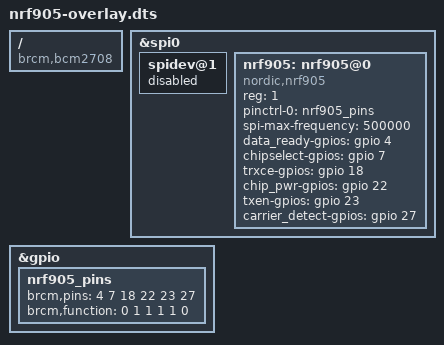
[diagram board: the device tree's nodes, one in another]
// Overlay for the Nordic Semiconductor NRF905 tranceiver
/dts-v1/;
/plugin/;

/ {
	compatible = "brcm,bcm2708";

	fragment@0 {
		target = <&spi0>;
		__overlay__ {
			#address-cells = <1>;
			#size-cells = <0>;

			status = "okay";

			spidev@1{
				status = "disabled";
			};

			nrf905: nrf905@0 {
				compatible = "nordic,nrf905";
				reg = <1>;
				pinctrl-names = "default";
				pinctrl-0 = <&nrf905_pins>;
				#address-cells = <1>;
				#size-cells = <0>;
				spi-max-frequency = <500000>;
				data_ready-gpios = <&gpio 4 0>;
				chipselect-gpios = <&gpio 7 0>;
				trxce-gpios = <&gpio 18 0>;
				chip_pwr-gpios = <&gpio 22 0>;
				txen-gpios = <&gpio 23 0>;
				carrier_detect-gpios = <&gpio 27 0>;
				status = "okay";
			};
		};
	};


	fragment@1 {
		target = <&gpio>;
		__overlay__ {
			nrf905_pins: nrf905_pins {
				brcm,pins = <4 7 18 22 23 27>;
				brcm,function = <0 1 1 1 1 0>;
				/* brcm,pull = <0>; */
			};
		};
	};
};
